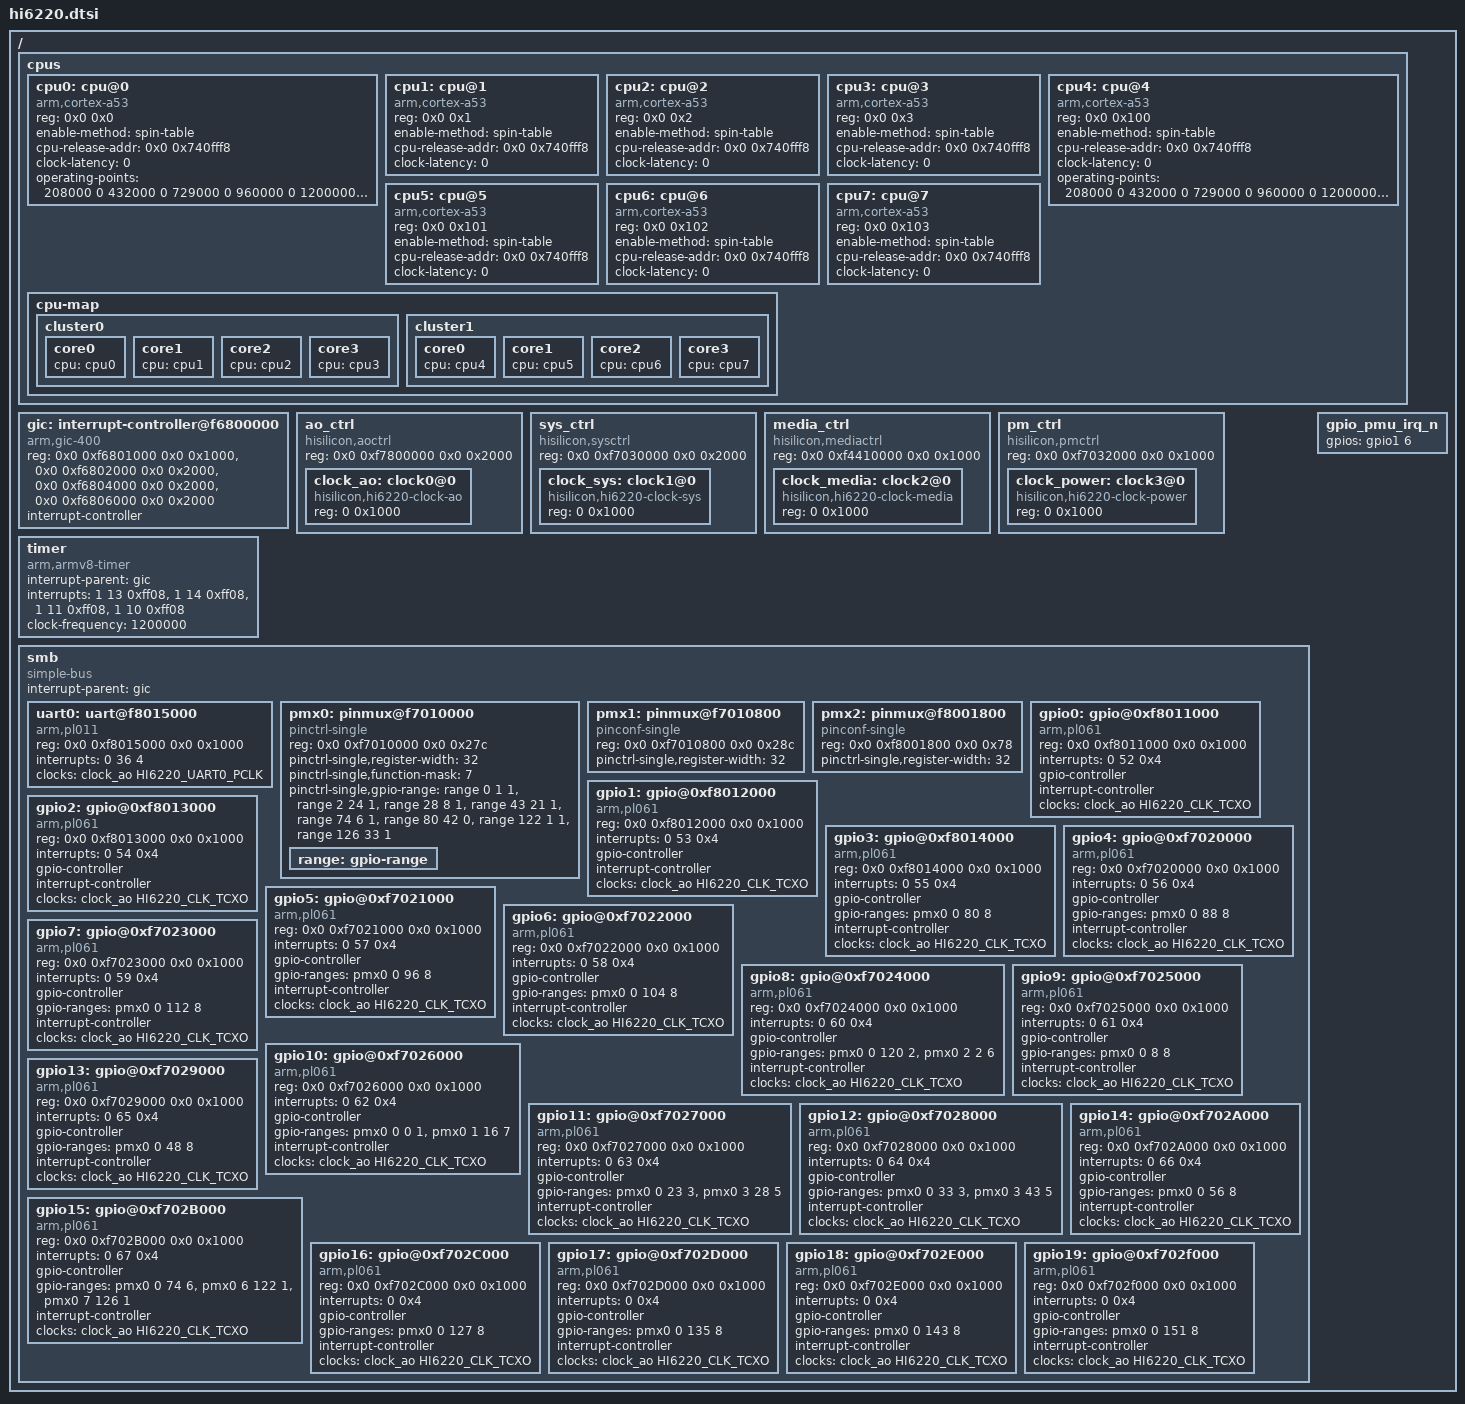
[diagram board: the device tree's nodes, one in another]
/*
 * dts file for Hisilicon Hi6220 SoC
 *
 * Copyright (C) 2014, Hisilicon Ltd.
 */

#include <dt-bindings/clock/hi6220-clock.h>

/ {
	cpus {
		#address-cells = <2>;
		#size-cells = <0>;

		cpu0: cpu@0 {
			compatible = "arm,cortex-a53", "arm,armv8";
			device_type = "cpu";
			reg = <0x0 0x0>;
                        enable-method = "spin-table";
                        cpu-release-addr = <0x0 0x740fff8>;
			clock-latency = <0>;
			operating-points = <
				/* kHz */
				208000   0
				432000   0
				729000   0
				960000   0
				1200000  0
			>;
		};
		cpu1: cpu@1 {
			compatible = "arm,cortex-a53", "arm,armv8";
			device_type = "cpu";
			reg = <0x0 0x1>;
			enable-method = "spin-table";
                        cpu-release-addr = <0x0 0x740fff8>;
			clock-latency = <0>;
		};
		cpu2: cpu@2 {
			compatible = "arm,cortex-a53", "arm,armv8";
			device_type = "cpu";
			reg = <0x0 0x2>;
			enable-method = "spin-table";
                        cpu-release-addr = <0x0 0x740fff8>;
			clock-latency = <0>;
		};
		cpu3: cpu@3 {
			compatible = "arm,cortex-a53", "arm,armv8";
			device_type = "cpu";
			reg = <0x0 0x3>;
			enable-method = "spin-table";
                        cpu-release-addr = <0x0 0x740fff8>;
			clock-latency = <0>;
		};
		cpu4: cpu@4 {
			compatible = "arm,cortex-a53", "arm,armv8";
			device_type = "cpu";
			reg = <0x0 0x100>;
			enable-method = "spin-table";
                        cpu-release-addr = <0x0 0x740fff8>;
			clock-latency = <0>;
			operating-points = <
				/* kHz */
				208000   0
				432000   0
				729000   0
				960000   0
				1200000  0
			>;
		};
		cpu5: cpu@5 {
			compatible = "arm,cortex-a53", "arm,armv8";
			device_type = "cpu";
			reg = <0x0 0x101>;
			enable-method = "spin-table";
                        cpu-release-addr = <0x0 0x740fff8>;
			clock-latency = <0>;
		};
		cpu6: cpu@6 {
			compatible = "arm,cortex-a53", "arm,armv8";
			device_type = "cpu";
			reg = <0x0 0x102>;
			enable-method = "spin-table";
                        cpu-release-addr = <0x0 0x740fff8>;
			clock-latency = <0>;
		};
		cpu7: cpu@7 {
			compatible = "arm,cortex-a53", "arm,armv8";
			device_type = "cpu";
			reg = <0x0 0x103>;
			enable-method = "spin-table";
                        cpu-release-addr = <0x0 0x740fff8>;
			clock-latency = <0>;
		};

		cpu-map {
			cluster0 {
				core0 {
					cpu = <&cpu0>;
				};
				core1 {
					cpu = <&cpu1>;
				};
				core2 {
					cpu = <&cpu2>;
				};
				core3 {
					cpu = <&cpu3>;
				};
			};
			cluster1 {
				core0 {
					cpu = <&cpu4>;
				};
				core1 {
					cpu = <&cpu5>;
				};
				core2 {
					cpu = <&cpu6>;
				};
				core3 {
					cpu = <&cpu7>;
				};
			};
		};
	};

	gic: interrupt-controller@f6800000 {
		compatible = "arm,gic-400", "arm,cortex-a15-gic";
		reg = <0x0 0xf6801000 0x0 0x1000>, /* GICD */
		      <0x0 0xf6802000 0x0 0x2000>, /* GICC */
		      <0x0 0xf6804000 0x0 0x2000>, /* GICH */
		      <0x0 0xf6806000 0x0 0x2000>; /* GICV */
		#interrupt-cells = <3>;
		#address-cells = <0>;
		interrupt-controller;
	};

	ao_ctrl: ao_ctrl {
		compatible = "hisilicon,aoctrl";
		#address-cells = <1>;
		#size-cells = <1>;
		reg = <0x0 0xf7800000 0x0 0x2000>;
		ranges = <0 0x0 0xf7800000 0x2000>;

		clock_ao: clock0@0 {
			compatible = "hisilicon,hi6220-clock-ao";
			reg = <0 0x1000>;
			#clock-cells = <1>;
		};
	};

	sys_ctrl: sys_ctrl {
		compatible = "hisilicon,sysctrl";
		#address-cells = <1>;
		#size-cells = <1>;
		reg = <0x0 0xf7030000 0x0 0x2000>;
		ranges = <0 0x0 0xf7030000 0x2000>;

		clock_sys: clock1@0 {
			compatible = "hisilicon,hi6220-clock-sys";
			reg = <0 0x1000>;
			#clock-cells = <1>;
		};
	};

	media_ctrl: media_ctrl {
		compatible = "hisilicon,mediactrl";
		#address-cells = <1>;
		#size-cells = <1>;
		reg = <0x0 0xf4410000 0x0 0x1000>;
		ranges = <0 0x0 0xf4410000 0x1000>;

		clock_media: clock2@0 {
			compatible = "hisilicon,hi6220-clock-media";
			reg = <0 0x1000>;
			#clock-cells = <1>;
		};
	};

	pm_ctrl: pm_ctrl {
		compatible = "hisilicon,pmctrl";
		#address-cells = <1>;
		#size-cells = <1>;
		reg = <0x0 0xf7032000 0x0 0x1000>;
		ranges = <0 0x0 0xf7032000 0x1000>;

		clock_power: clock3@0 {
			compatible = "hisilicon,hi6220-clock-power";
			reg = <0 0x1000>;
			#clock-cells = <1>;
		};
	};

	timer {
		compatible = "arm,armv8-timer";
		interrupt-parent = <&gic>;
		interrupts = <1 13 0xff08>,
			     <1 14 0xff08>,
			     <1 11 0xff08>,
			     <1 10 0xff08>;
		clock-frequency = <1200000>;
	};

	smb {
		compatible = "simple-bus";
		#address-cells = <2>;
		#size-cells = <2>;
		interrupt-parent = <&gic>;
		ranges;

		uart0: uart@f8015000 {	/* console */
			compatible = "arm,pl011", "arm,primecell";
			reg = <0x0 0xf8015000 0x0 0x1000>;
			interrupts = <0 36 4>;
			clocks = <&clock_ao HI6220_UART0_PCLK>;
			clock-names = "apb_pclk";
			status = "ok";
		};

		pmx0: pinmux@f7010000 {
			compatible = "pinctrl-single";
			reg = <0x0 0xf7010000  0x0 0x27c>;
			#address-cells = <1>;
			#size-cells = <1>;
			#gpio-range-cells = <3>;
			pinctrl-single,register-width = <32>;
			pinctrl-single,function-mask = <7>;
			pinctrl-single,gpio-range = <
				&range 0  1  1
				&range 2  24  1
				&range 28  8  1
				&range 43  21  1
				&range 74  6  1
				&range 80  42  0
				&range 122  1  1
				&range 126  33  1
			>;
			range: gpio-range {
				#pinctrl-single,gpio-range-cells = <3>;
			};
		};

		pmx1: pinmux@f7010800 {
			compatible = "pinconf-single";
			reg = <0x0 0xf7010800 0x0 0x28c>;
			#address-cells = <1>;
			#size-cells = <1>;
			pinctrl-single,register-width = <32>;
		};

		pmx2: pinmux@f8001800 {
			compatible = "pinconf-single";
			reg = <0x0 0xf8001800 0x0 0x78>;
			#address-cells = <1>;
			#size-cells = <1>;
			pinctrl-single,register-width = <32>;
		};

		gpio0: gpio@0xf8011000 {
			compatible = "arm,pl061", "arm,primecell";
			reg = <0x0 0xf8011000 0x0 0x1000>;
			interrupts = <0 52 0x4>;
			gpio-controller;
			#gpio-cells = <2>;
			interrupt-controller;
			#interrupt-cells = <2>;
			clocks = <&clock_ao HI6220_CLK_TCXO>;
			clock-names = "apb_pclk";
			status = "ok";
		};

		gpio1: gpio@0xf8012000 {
			compatible = "arm,pl061", "arm,primecell";
			reg = <0x0 0xf8012000 0x0 0x1000>;
			interrupts = <0 53 0x4>;
			gpio-controller;
			#gpio-cells = <2>;
			interrupt-controller;
			#interrupt-cells = <2>;
			clocks = <&clock_ao HI6220_CLK_TCXO>;
			clock-names = "apb_pclk";
			status = "ok";
		};

		gpio2: gpio@0xf8013000 {
			compatible = "arm,pl061", "arm,primecell";
			reg = <0x0 0xf8013000 0x0 0x1000>;
			interrupts = <0 54 0x4>;
			gpio-controller;
			#gpio-cells = <2>;
			interrupt-controller;
			#interrupt-cells = <2>;
			clocks = <&clock_ao HI6220_CLK_TCXO>;
			clock-names = "apb_pclk";
			status = "ok";
		};

		gpio3: gpio@0xf8014000 {
			compatible = "arm,pl061", "arm,primecell";
			reg = <0x0 0xf8014000 0x0 0x1000>;
			interrupts = <0 55 0x4>;
			gpio-controller;
			#gpio-cells = <2>;
			gpio-ranges = <&pmx0 0 80 8>;
			interrupt-controller;
			#interrupt-cells = <2>;
			clocks = <&clock_ao HI6220_CLK_TCXO>;
			clock-names = "apb_pclk";
			status = "ok";
		};

		gpio4: gpio@0xf7020000 {
			compatible = "arm,pl061", "arm,primecell";
			reg = <0x0 0xf7020000 0x0 0x1000>;
			interrupts = <0 56 0x4>;
			gpio-controller;
			#gpio-cells = <2>;
			gpio-ranges = <&pmx0 0 88 8>;
			interrupt-controller;
			#interrupt-cells = <2>;
			clocks = <&clock_ao HI6220_CLK_TCXO>;
			clock-names = "apb_pclk";
			status = "ok";
		};

		gpio5: gpio@0xf7021000 {
			compatible = "arm,pl061", "arm,primecell";
			reg = <0x0 0xf7021000 0x0 0x1000>;
			interrupts = <0 57 0x4>;
			gpio-controller;
			#gpio-cells = <2>;
			gpio-ranges = <&pmx0 0 96 8>;
			interrupt-controller;
			#interrupt-cells = <2>;
			clocks = <&clock_ao HI6220_CLK_TCXO>;
			clock-names = "apb_pclk";
			status = "ok";
		};

		gpio6: gpio@0xf7022000 {
			compatible = "arm,pl061", "arm,primecell";
			reg = <0x0 0xf7022000 0x0 0x1000>;
			interrupts = <0 58 0x4>;
			gpio-controller;
			#gpio-cells = <2>;
			gpio-ranges = <&pmx0 0 104 8>;
			interrupt-controller;
			#interrupt-cells = <2>;
			clocks = <&clock_ao HI6220_CLK_TCXO>;
			clock-names = "apb_pclk";
			status = "ok";
		};

		gpio7: gpio@0xf7023000 {
			compatible = "arm,pl061", "arm,primecell";
			reg = <0x0 0xf7023000 0x0 0x1000>;
			interrupts = <0 59 0x4>;
			gpio-controller;
			#gpio-cells = <2>;
			gpio-ranges = <&pmx0 0 112 8>;
			interrupt-controller;
			#interrupt-cells = <2>;
			clocks = <&clock_ao HI6220_CLK_TCXO>;
			clock-names = "apb_pclk";
			status = "ok";
		};

		gpio8: gpio@0xf7024000 {
			compatible = "arm,pl061", "arm,primecell";
			reg = <0x0 0xf7024000 0x0 0x1000>;
			interrupts = <0 60 0x4>;
			gpio-controller;
			#gpio-cells = <2>;
			gpio-ranges = <&pmx0 0 120 2 &pmx0 2 2 6>;
			interrupt-controller;
			#interrupt-cells = <2>;
			clocks = <&clock_ao HI6220_CLK_TCXO>;
			clock-names = "apb_pclk";
			status = "ok";
		};

		gpio9: gpio@0xf7025000 {
			compatible = "arm,pl061", "arm,primecell";
			reg = <0x0 0xf7025000 0x0 0x1000>;
			interrupts = <0 61 0x4>;
			gpio-controller;
			#gpio-cells = <2>;
			gpio-ranges = <&pmx0 0 8 8>;
			interrupt-controller;
			#interrupt-cells = <2>;
			clocks = <&clock_ao HI6220_CLK_TCXO>;
			clock-names = "apb_pclk";
			status = "ok";
		};

		gpio10: gpio@0xf7026000 {
			compatible = "arm,pl061", "arm,primecell";
			reg = <0x0 0xf7026000 0x0 0x1000>;
			interrupts = <0 62 0x4>;
			gpio-controller;
			#gpio-cells = <2>;
			gpio-ranges = <&pmx0 0 0 1 &pmx0 1 16 7>;
			interrupt-controller;
			#interrupt-cells = <2>;
			clocks = <&clock_ao HI6220_CLK_TCXO>;
			clock-names = "apb_pclk";
			status = "ok";
		};

		gpio11: gpio@0xf7027000 {
			compatible = "arm,pl061", "arm,primecell";
			reg = <0x0 0xf7027000 0x0 0x1000>;
			interrupts = <0 63 0x4>;
			gpio-controller;
			#gpio-cells = <2>;
			gpio-ranges = <&pmx0 0 23 3 &pmx0 3 28 5>;
			interrupt-controller;
			#interrupt-cells = <2>;
			clocks = <&clock_ao HI6220_CLK_TCXO>;
			clock-names = "apb_pclk";
			status = "ok";
		};

		gpio12: gpio@0xf7028000 {
			compatible = "arm,pl061", "arm,primecell";
			reg = <0x0 0xf7028000 0x0 0x1000>;
			interrupts = <0 64 0x4>;
			gpio-controller;
			#gpio-cells = <2>;
			gpio-ranges = <&pmx0 0 33 3 &pmx0 3 43 5>;
			interrupt-controller;
			#interrupt-cells = <2>;
			clocks = <&clock_ao HI6220_CLK_TCXO>;
			clock-names = "apb_pclk";
			status = "ok";
		};

		gpio13: gpio@0xf7029000 {
			compatible = "arm,pl061", "arm,primecell";
			reg = <0x0 0xf7029000 0x0 0x1000>;
			interrupts = <0 65 0x4>;
			gpio-controller;
			#gpio-cells = <2>;
			gpio-ranges = <&pmx0 0 48 8>;
			interrupt-controller;
			#interrupt-cells = <2>;
			clocks = <&clock_ao HI6220_CLK_TCXO>;
			clock-names = "apb_pclk";
			status = "ok";
		};

		gpio14: gpio@0xf702A000 {
			compatible = "arm,pl061", "arm,primecell";
			reg = <0x0 0xf702A000 0x0 0x1000>;
			interrupts = <0 66 0x4>;
			gpio-controller;
			#gpio-cells = <2>;
			gpio-ranges = <&pmx0 0 56 8>;
			interrupt-controller;
			#interrupt-cells = <2>;
			clocks = <&clock_ao HI6220_CLK_TCXO>;
			clock-names = "apb_pclk";
			status = "ok";
		};

		gpio15: gpio@0xf702B000 {
			compatible = "arm,pl061", "arm,primecell";
			reg = <0x0 0xf702B000 0x0 0x1000>;
			interrupts = <0 67 0x4>;
			gpio-controller;
			#gpio-cells = <2>;
			gpio-ranges = <
				&pmx0 0 74 6
				&pmx0 6 122 1
				&pmx0 7 126 1
			>;
			interrupt-controller;
			#interrupt-cells = <2>;
			clocks = <&clock_ao HI6220_CLK_TCXO>;
			clock-names = "apb_pclk";
			status = "ok";
		};

		gpio16: gpio@0xf702C000 {
			compatible = "arm,pl061", "arm,primecell";
			reg = <0x0 0xf702C000 0x0 0x1000>;
			interrupts = <0  0x4>;
			gpio-controller;
			#gpio-cells = <2>;
			gpio-ranges = <&pmx0 0 127 8>;
			interrupt-controller;
			#interrupt-cells = <2>;
			clocks = <&clock_ao HI6220_CLK_TCXO>;
			clock-names = "apb_pclk";
			status = "ok";
		};

		gpio17: gpio@0xf702D000 {
			compatible = "arm,pl061", "arm,primecell";
			reg = <0x0 0xf702D000 0x0 0x1000>;
			interrupts = <0  0x4>;
			gpio-controller;
			#gpio-cells = <2>;
			gpio-ranges = <&pmx0 0 135 8>;
			interrupt-controller;
			#interrupt-cells = <2>;
			clocks = <&clock_ao HI6220_CLK_TCXO>;
			clock-names = "apb_pclk";
			status = "ok";
		};

		gpio18: gpio@0xf702E000 {
			compatible = "arm,pl061", "arm,primecell";
			reg = <0x0 0xf702E000 0x0 0x1000>;
			interrupts = <0  0x4>;
			gpio-controller;
			#gpio-cells = <2>;
			gpio-ranges = <&pmx0 0 143 8>;
			interrupt-controller;
			#interrupt-cells = <2>;
			clocks = <&clock_ao HI6220_CLK_TCXO>;
			clock-names = "apb_pclk";
			status = "ok";
		};

		gpio19: gpio@0xf702f000{
			compatible = "arm,pl061", "arm,primecell";
			reg = <0x0 0xf702f000 0x0 0x1000>;
			interrupts = <0  0x4>;
			gpio-controller;
			#gpio-cells = <2>;
			gpio-ranges = <&pmx0 0 151 8>;
			interrupt-controller;
			#interrupt-cells = <2>;
			clocks = <&clock_ao HI6220_CLK_TCXO>;
			clock-names = "apb_pclk";
			status = "ok";
		};
	};

	gpio_pmu_irq_n:gpio_pmu_irq_n {
		gpios = <&gpio1 6 0>;
	};
};
